# psc3 register map
Vendor: Infineon Technologies; Series: PSC3; File version: 1.0
CPU: CM33 r0p1, little endian, MPU, FPU, VTOR, 3 interrupt priority bits
Registers are 32-bit, read-write, reset 0x0 unless marked. A register's access mark holds for its fields unless they carry their own. Offsets are from the block's base; [hi:lo] are bit positions; lines under a group give offsets from that group; {n}, {i} and the like mark numbered series; 'fields as' and 'values as' point back to an identical list; <NAME> marks a mode.

## SRSS (part 2 of 3) — SRSS Core Registers
Base 0x42200000
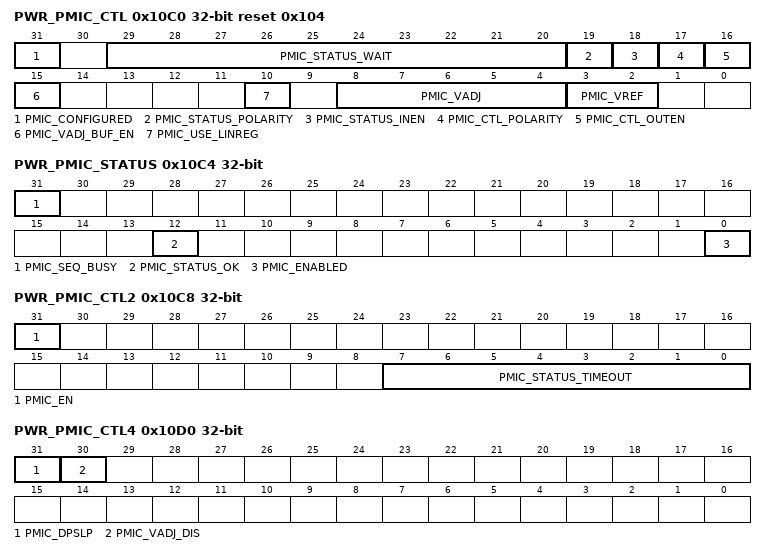
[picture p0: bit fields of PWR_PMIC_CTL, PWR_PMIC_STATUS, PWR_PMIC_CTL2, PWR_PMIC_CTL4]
0x10C0 PWR_PMIC_CTL reset 0x104 — PMIC Control Register
  [31] PMIC_CONFIGURED — Indicates the PMIC has been configured. This is used to know if PMIC should be enabled in response to a debug power up request. Do not change PMIC settings after this bit is set high.
  [29:20] PMIC_STATUS_WAIT — Wait count in 4us steps after PMIC status ok. This is used by the hardware sequencer to allow additional settling time before disabling the internal regulator. The LSB is 32 IMO periods which results in a nominal LSB step of 4us.
  [19] PMIC_STATUS_POLARITY — The polarity used to trigger a reset action based on the PMIC status input. The reset system triggers a reset when the unmasked PMIC status matches this value.
  [18] PMIC_STATUS_INEN — Input buffer enable for PMIC status input. Set this bit high to enable the input receiver.
  [17] PMIC_CTL_POLARITY — Polarity used to enable the PMIC. The sequencer uses PMIC_CTL_POLARITY to enable the PMIC, and it uses the complement to disable the PMIC.
  [16] PMIC_CTL_OUTEN — Output enable for PMIC enable pin. Set this bit high to enable the driver on this pin.
  [15] PMIC_VADJ_BUF_EN — Analog buffer enable on voltage adjust output. Write this bit depending on the type of PMIC connected: 0: Bypass buffer. This connects the resistor divider directly to the output pin. Use this setting for a PMIC with a high-impedance feedback input, such as those that support a resistor divider on the PCB. This setting can also be used with a low-impedance PMIC with PMIC_VREF=2'b11 (no scaling). 1: Use analog buffer. This enables an analog buffer between the resistor divider output and the pin. The buffer can drive a resistor divider on the PCB that feeds into the PMIC feedback input. This allows targeting a different PMIC reference voltage from PMIC_VREF choices, while still supporting voltage adjustment using the internal divider.
  [10] PMIC_USE_LINREG — Controls whether hardware sequencer keeps the internal Active Linear Regulator enabled to improve supply supervision of vccd. When using this feature, if the PMIC fails to keep vccd above the internal regulator target, then the internal regulator will attempt to recover vccd. If the regulator current is too high, the regulator triggers an over-current detector (OCD) reset. 0: Internal Active Linear Regulator disabled after PMIC enabled. OCD is disabled.; 1: Internal Active Linear Regulator kept enabled. See datasheet for minimum PMIC vccd input to prevent OCD.
  [8:4] PMIC_VADJ — Voltage adjustment output setting. The lookup table in this field requires the proper setting in PMIC_VREF for the chosen PMIC. This field has no effect when PMIC_VREF selects no scaling. The feedback tap point is at a vccd pad inside the chip, so the voltage may be a little higher at the PMIC output. 0x03: 1.040V, 0x04: 1.049V, 0x05: 1.057V, 0x06: 1.066V, 0x07: 1.074V, 0x08: 1.083V, 0x09: 1.091V, 0x0A: 1.099V, 0x0B: 1.108V, 0x0C: 1.116V, 0x0D: 1.125V, 0x0E: 1.133V, 0x0F: 1.142V, 0x10: 1.150V, 0x11: 1.158V, 0x12: 1.167V, 0x13: 1.175V, 0x14: 1.184V, 0x15: 1.192V, 0x16: 1.201V, 0x17: 1.209V, 0x18: 1.218V, 0x19: 1.226V, 0x1A: 1.234V, 0x1B: 1.243V, 0x1C: 1.251V, others: Illegal. Behavior is undefined.
  [3:2] PMIC_VREF — PMIC reference voltage setting. This selects the scaling factor used to generate the output voltage (vout) given the feedback voltage (vfb) for the chosen PMIC. For a PMIC that compares vfb to an internal reference voltage (vref) according to the formula vout=vref/vfb, select that vref below. For a PMIC that contains an internal resistor divider and expects an unscaled feedback voltage, use the 'No scaling' choice. 2'b00: Scale for vref=0.9V, use PMIC_VADJ to set the vccd target; 2'b01: Scale for vref=0.8V, use PMIC_VADJ to set the vccd target; 2'b10: Scale for vref=0.6V, use PMIC_VADJ to set the vccd target; 2'b11: No scaling, PMIC_VADJ has no effect
0x10C4 PWR_PMIC_STATUS ro — PMIC Status Register
  [31] PMIC_SEQ_BUSY — Indicates the PMIC enable/disable sequencer is busy transitioning to/from PMIC. 0: Sequencer is not busy; 1: Sequencer is busy either enabling or disabling PMIC.
  [12] PMIC_STATUS_OK — Indicates the PMIC status is ok. This includes polarity adjustment according to PMIC_STATUS_POLARITY. 0: PMIC status is not ok or PMIC input buffer is disabled (PMIC_STATUS_INEN==0); 1: PMIC status input buffer is enabled and indicates ok
  [0] PMIC_ENABLED — Indicates the state of the PMIC enable/disable sequencer. This bit is only valid when PMIC_SEQ_BUSY==0. 0: PMIC sequencer indicates PMIC is disabled. 1: PMIC sequencer indicates PMIC is enabled.
0x10C8 PWR_PMIC_CTL2 — PMIC Control Register 2
  [31] PMIC_EN — Enable PMIC. This bit will not set if PMIC_CONFIGURED==0. Use PWR_PMIC_STATUS.ENABLED to know the actual status of PMIC. It will differ from this bit in the following cases: A) Do not enter DEEPSLEEP while the sequencer is busy (see PWR_PMIC_STATUS.PMIC_SEQ_BUSY). The hardware sequencer disables PMIC during DEEPSLEEP entry and enables it upon wakeup. B) The debugger requests the chip remain powered up. Hardware prevents PMIC from disabling when this bit is cleared. Hardware does not automatically enable PMIC in response to debugger power up request. If this bit is low when the debugger deasserts the power up request, the hardware sequencer will disable PMIC.
  [7:0] PMIC_STATUS_TIMEOUT — Timeout while waiting for PMIC_STATUS_OK==1 when switching to PMIC. 0: disables timeout. Do not change this register after setting PWR_PMIC_CTL.PMIC_CONFIGURED. >0: enables timeout of PMIC_STATUS_TIMEOUT*128us (nominal, clocked by IMO). Timeout expiration triggers reset.
0x10D0 PWR_PMIC_CTL4 — PMIC Control Register 4
  [31] PMIC_DPSLP — Configures PMIC behavior during DEEPSLEEP. 0: Device operates from internal regulators during DEEPSLEEP. If PMIC is enabled at the beginning of the DEEPSLEEP transition, hardware changes to the internal regulators and disables the PMIC. 1: DEEPSLEEP transition does not change PMIC enable.
  [30] PMIC_VADJ_DIS — Disables the VADJ circuitry. This can be used to decrease current consumption if the entire feedback network is outside the device. 0: Device generates VADJ when PMIC is enabled. This allows the feedback loop to compensate for voltage drops in the PCB and package. 1: Device does not generate VADJ, and it must not be part of the PMIC feedback loop. This reduces current by turning off the internal resistor divider that generates VADJ.
{0x1200+4i} CLK_PATH_SELECT[{i}] (i=0..15) — Clock Path Select Register
  [2:0] PATH_MUX — Selects a source for clock PATH<i>. Note that not all products support all clock sources. Selecting a clock source that is not supported will result in undefined behavior. It takes four cycles of the originally selected clock to switch away from it. Do not disable the original clock during this time.
    0=IMO (IMO - Internal R/C Oscillator); 1=EXTCLK (EXTCLK - External Clock Pin); 2=ECO (ECO - External-Crystal Oscillator); 3=ALTHF (ALTHF - Alternate High-Frequency clock input (product-specific clock)); 4=DSI_MUX (DSI_MUX - Output of DSI mux for this path. Using a DSI source directly as root of HFCLK will result in undefined behavior.); 5=LPECO (LPECO - Low-Power External-Crystal Oscillator); 6=IHO (IHO - Internal High-speed Oscillator)
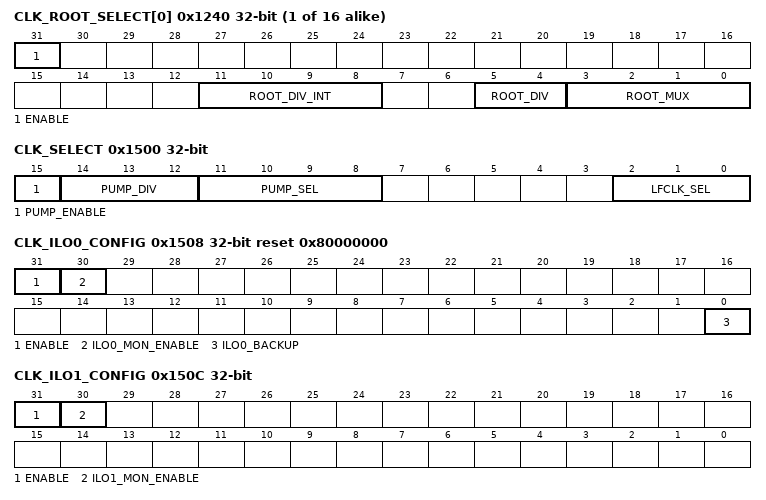
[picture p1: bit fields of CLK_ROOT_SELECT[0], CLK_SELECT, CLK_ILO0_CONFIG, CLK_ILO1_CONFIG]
{0x1240+4i} CLK_ROOT_SELECT[{i}] (i=0..15) — Clock Root Select Register
  [31] ENABLE — Enable for this clock root. All clock roots default to disabled (ENABLE==0) except HFCLK0, which cannot be disabled.
  [11:8] ROOT_DIV_INT — Selects predivider value for this clock root and DSI input. This divider is after DIRECT_MUX. For products with DSI, the output of this mux is routed to DSI for use as a signal. For products with clock supervision, the output of this mux is the monitored clock for CSV_HF<k>.
    0=NO_DIV (Transparent mode, feed through selected clock source w/o dividing.); {v}=DIV_BY_{v+1} (Divide selected clock source by {v+1}) (v=1..15)
  [5:4] ROOT_DIV — Obsolete. Do not use in new designs.
  [3:0] ROOT_MUX — Selects a clock path for HFCLK<k> and SRSS DSI input <k>. The output of this mux goes to the direct mux (see CLK_DIRECT_SELECT). Use CLK_SELECT_PATH[i] to configure the desired path. The number of clock paths is product-specific, and selecting an unimplemented path is not supported. Some paths may have FLL or PLL available (product-specific), and the control and bypass mux selections of these are in other registers. Configure the FLL using CLK_FLL_CONFIG register. Configure a PLL using the related CLK_PLL_CONFIG[k] register. Note that not all products support all clock sources. Selecting a clock source that is not supported will result in undefined behavior. It takes four cycles of the originally selected clock to switch away from it. Do not disable the original clock during this time.
    {v}=PATH{v} (Select PATH{v}) (v=0..15)
{0x1280+4i} CLK_DIRECT_SELECT[{i}] (i=0..15) — Clock Root Direct Select Register
  [8] DIRECT_MUX — Direct selection mux that allows IMO to bypass most of the clock mux structure. For products with multiple regulators, this mux can be used to reduce current without requiring significant reconfiguration of the clocking network. The default value of HFCLK<0>==ROOT_MUX, and the default value for other clock trees is product-specific.
    0=IMO (Select IMO); 1=ROOT_MUX (Select ROOT_MUX selection)
0x1400 CSV_HF group — Clock Supervisor (CSV) registers for Root clocks
  {0x0+0x10*j} CSV[{j}] (j=0..6) group — Active domain Clock Supervisor (CSV) registers
    0x00 REF_CTL — Clock Supervision Reference Control
      [31] CSV_EN — Enables clock supervision, both frequency and loss. CSV in Active domain: Clock supervision is reset during DeepSleep and Hibernate modes. When enabled it begins operating automatically after a DeepSleep wakeup, but it must be reconfigured after Hibernate wakeup. CSV in DeepSleep domain: Clock supervision is reset during Hibernate mode. It must be reconfigured after Hibernate wakeup. A CSV error detection is reported to the Fault structure, or instead it can generate a power reset.
      [30] CSV_ACTION — Specifies the action taken when an anomaly is detected on the monitored clock. CSV in DeepSleep domain always do a Fault report (which also wakes up the system).
        0=FAULT (Generate a fault); 1=RESET (Cause a power reset. This should only be used for clk_hf0.)
      [15:0] STARTUP — Startup delay time -1 (in reference clock cycles), after enable or DeepSleep wakeup, from reference clock start to monitored clock start. At a minimum (both clocks running): STARTUP >= (PERIOD +3) * FREQ_RATIO - UPPER, with FREQ_RATIO = (Reference frequency / Monitored frequency) On top of that the actual clock startup delay and the margin for accuracy of both clocks must be added.
    0x04 REF_LIMIT — Clock Supervision Reference Limits
      [31:16] UPPER — Cycle time upper limit. Set the upper limit -1, in reference clock cycles, before (or same time) the next monitored clock event must happen. If a monitored clock event does not happen before this limit is reached, or does not happen at all (clock loss), a CSV error is detected.
      [15:0] LOWER — Cycle time lower limit. Set the lower limit -1, in reference clock cycles, before the next monitored clock event is allowed to happen. If a monitored clock event happens before this limit is reached a CSV error is detected. LOWER must be at least 1 less than UPPER. In case the clocks are asynchronous LOWER must be at least 3 less than UPPER.
    0x08 MON_CTL — Clock Supervision Monitor Control
      [15:0] PERIOD — Period time. Set the Period -1, in monitored clock cycles, before the next monitored clock event happens. PERIOD <= (UPPER+1) / FREQ_RATIO -1, with FREQ_RATIO = (Reference frequency / Monitored frequency) In case the clocks are asynchronous: PERIOD <= UPPER / FREQ_RATIO -1 Additionally margin must be added for accuracy of both clocks.
0x1500 CLK_SELECT — Clock selection register
  [15] PUMP_ENABLE — Enable the pump clock. PUMP_ENABLE and the PUMP_SEL mux are not glitch-free to minimize side-effects, avoid changing the PUMP_SEL and PUMP_DIV while changing PUMP_ENABLE. To change the settings, do the following: 1) If the pump clock is enabled, write PUMP_ENABLE=0 without changing PUMP_SEL and PUMP_DIV. 2) Change PUMP_SEL and PUMP_DIV to desired settings with PUMP_ENABLE=0. 3) Write PUMP_ENABLE=1 without changing PUMP_SEL and PUMP_DIV.
  [14:12] PUMP_DIV — Division ratio for PUMPCLK. Uses selected PUMP_SEL clock as the source.
    0=NO_DIV (Transparent mode, feed through selected clock source w/o dividing.); 1=DIV_BY_2 (Divide selected clock source by 2); 2=DIV_BY_4 (Divide selected clock source by 4); 3=DIV_BY_8 (Divide selected clock source by 8); 4=DIV_BY_16 (Divide selected clock source by 16)
  [11:8] PUMP_SEL — Selects clock PATH<k>, where k=PUMP_SEL. The output of this mux goes to the PUMP_DIV to make PUMPCLK Each product has a specific number of available clock paths. Selecting a path that is not implemented on a product will result in undefined behavior. Note that this is not a glitch free mux.
  [2:0] LFCLK_SEL — Select source for LFCLK. Note that not all products support all clock sources. Selecting a clock source that is not supported will result in undefined behavior. Writes to this field are ignored unless the WDT is unlocked using WDT_LOCK register. It takes four cycles of the originally selected clock to switch away from it. Do not disable the original clock during this time.
    0=ILO (ILO - Internal Low-speed Oscillator); 1=WCO (WCO - Watch-Crystal Oscillator. Requires Backup domain to be present and properly configured (including external watch crystal, if used).); 2=ALTLF (ALTLF - Alternate Low-Frequency Clock. Capability is product-specific); 3=PILO (PILO - Precision ILO, if present.); 4=ILO1 (ILO1 - Internal Low-speed Oscillator #1, if present.); 5=ECO_PRESCALER (ECO_PRESCALER - External-Crystal Oscillator after prescaling, if present. Does not work in DEEPSLEEP or HIBERNATE modes. Intended for applications that operate in ACTIVE/SLEEP modes only. This option is only valid when ECO is present in the product. Not compatible with an clk_sys frequency <48MHz.); 6=LPECO_PRESCALER (LPECO_PRESCALER - Low-Power External-Crystal Oscillator after prescaling, if present. This choice works in ACTIVE/SLEEP/DEEPSLEEP modes. This option is only valid when LPECO is present in the product.)
0x1508 CLK_ILO0_CONFIG reset 0x80000000 — ILO0 Configuration
  [31] ENABLE — Master enable for ILO. Writes to this field are ignored unless the WDT is unlocked using WDT_LOCK register. HT-variant: This register will not clear unless PWR_CTL2.BGREF_LPMODE==0. After enabling, the first ILO0 cycle occurs within 12us and is +/-10 percent accuracy. Thereafter, ILO0 is +/-5 percent accurate.
  [30] ILO0_MON_ENABLE
  [0] ILO0_BACKUP — This register indicates that ILO0 should stay enabled during XRES and HIBERNATE modes. If backup voltage domain is implemented on the product, this bit also indicates if ILO0 should stay enabled through power-related resets on other supplies, e.g.. BOD on VDDD/VCCD. Writes to this field are ignored unless the WDT is unlocked. This register is reset when the backup logic resets. 0: ILO0 turns off during XRES, HIBERNATE, and power-related resets. ILO0 configuration and trims are reset by these events. 1: ILO0 stays enabled, as described above. ILO0 configuration and trims are not reset by these events.
0x150C CLK_ILO1_CONFIG — ILO1 Configuration
  [31] ENABLE — Master enable for ILO1. HT-variant: After enabling, the first ILO1 cycle occurs within 12us and is +/-10 percent accuracy. Thereafter, ILO1 is +/-5 percent accurate.
  [30] ILO1_MON_ENABLE
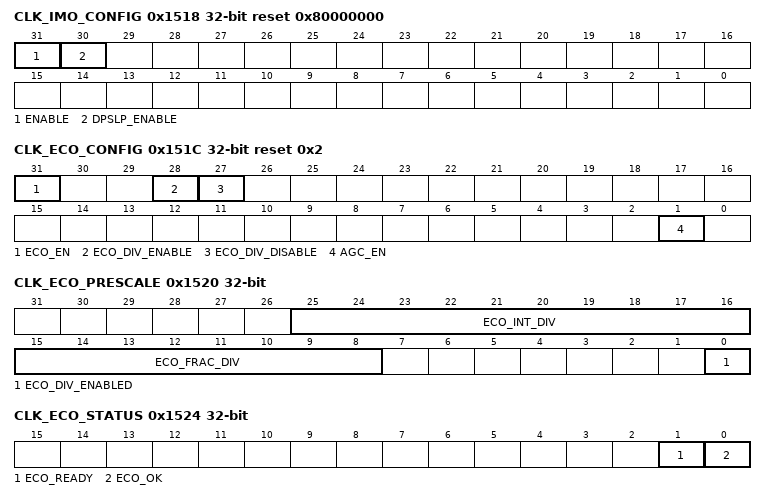
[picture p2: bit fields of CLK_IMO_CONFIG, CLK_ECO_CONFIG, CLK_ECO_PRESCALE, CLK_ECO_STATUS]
0x1518 CLK_IMO_CONFIG reset 0x80000000 — IMO Configuration
  [31] ENABLE — Master enable for IMO oscillator. This bit must be high at all times for all functions to work properly. Hardware will automatically disable the IMO during HIBERNATE and XRES. It will automatically disable during DEEPSLEEP if DPSLP_ENABLE==0.
  [30] DPSLP_ENABLE — Enable for IMO during DEEPSLEEP. This bit configures IMO behavior during DEEPSLEEP: 0: IMO is automatically disabled during DEEPSLEEP and enables upon wakeup; 1: IMO is kept enabled throughout DEEPSLEEP
0x151C CLK_ECO_CONFIG reset 0x2 — ECO Configuration Register
  [31] ECO_EN — Master enable for ECO oscillator. Configure the settings in CLK_ECO_CONFIG2 to work with the selected crystal, before enabling ECO.
  [28] ECO_DIV_ENABLE — ECO prescaler enable command (mutually exclusive with ECO_DIV_DISABLE). ECO Prescaler only works in ACTIVE and SLEEP modes. SW sets this field to '1' to enable the divider and HW sets this field to '0' to indicate that divider enabling has completed. When the divider is enabled, its integer and fractional counters are initialized to '0'. If a divider is to be re-enabled using different integer and fractional divider values, the SW should follow these steps: 0: Disable the divider using the ECO_DIV_DISABLE field. 1: Configure CLK_ECO_PRESCALE registers. 2: Enable the divider using the ECO_DIV_ENABLE field. HW sets the ECO_DIV_ENABLE field to '0' when the enabling is performed and HW set CLK_ECO_PRESCALER.ENABLED to '1' when the enabling is performed.
  [27] ECO_DIV_DISABLE — ECO prescaler disable command (mutually exclusive with ECO_DIV_ENABLE). SW sets this field to '1' and HW sets this field to '0'. HW sets ECO_DIV_DISABLE field to '0' immediately and HW sets CLK_ECO_PRESCALE.ECO_DIV_EN field to '0' immediately.
  [1] AGC_EN — Automatic Gain Control (AGC) enable. When set, the oscillation amplitude is controlled to the level selected by CLK_ECO_CONFIG2.ATRIM. When low, the amplitude is not explicitly controlled and can be as high as the vddd supply. WARNING: use care when disabling AGC because driving a crystal beyond its rated limit can permanently damage the crystal.
0x1520 CLK_ECO_PRESCALE — ECO Prescaler Configuration Register
  [25:16] ECO_INT_DIV — 10-bit integer value allows for ECO frequencies up to 33.55MHz. Subtract one from the desired divide value when writing this field. For example, to divide by 1, write ECO_INT_DIV=0. Do not change this setting when ECO Prescaler is enabled.
  [15:8] ECO_FRAC_DIV — 8-bit fractional value, sufficient to get prescaler output within the +/-65ppm calibration range. Do not change this setting when ECO Prescaler is enabled.
  [0] ECO_DIV_ENABLED ro — ECO prescaler enabled. HW sets this field to '1' as a result of an CLK_ECO_CONFIG.ECO_DIV_ENABLE command. HW sets this field to '0' as a result on a CLK_ECO_CONFIG.ECO_DIV_DISABLE command. ECO prescaler is incompatible with DEEPSLEEP modes, and firmware must disable it before entering DEEPSLEEP.
0x1524 CLK_ECO_STATUS ro — ECO Status Register
  [1] ECO_READY — Indicates the ECO internal oscillator circuit has had enough time to fully stabilize. This is the output of a counter since ECO was enabled, and it does not check the ECO output. It is recommended to also confirm ECO_OK==1.
  [0] ECO_OK — Indicates the ECO internal oscillator circuit has sufficient amplitude. It may not meet the PPM accuracy or duty cycle spec.
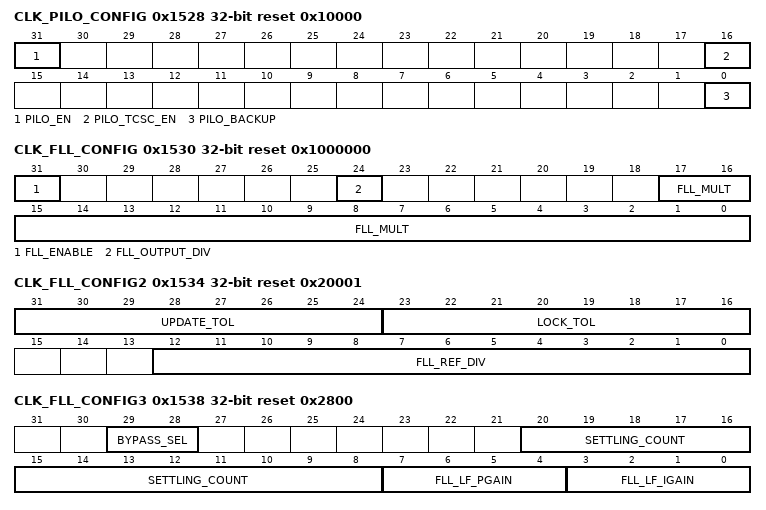
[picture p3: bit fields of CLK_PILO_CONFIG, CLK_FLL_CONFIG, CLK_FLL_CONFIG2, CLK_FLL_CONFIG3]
0x1528 CLK_PILO_CONFIG reset 0x10000 — Precision ILO Configuration Register
  [31] PILO_EN — Enable PILO. If the PILO is the selected source for WDT, writes to this field are ignored unless the WDT is unlocked using WDT_LOCK register.
  [16] PILO_TCSC_EN — PILO second order temperature curvature correction enable. If the PILO is the selected source for WDT, writes to this field are ignored unless the WDT is unlocked using WDT_LOCK register. 0: Disable second order temperature curvature correction. 1: Enable second order temperature curvature correction.
  [0] PILO_BACKUP — If backup domain is present on this product, this register indicates that PILO should stay enabled for use by backup domain during XRES, and HIBERNATE mode. If backup voltage domain is implemented on the product, PILO should stay enabled through power-related resets on other supplies, e.g.. BOD on VDDD/VCCD. If the PILO is the selected source for WDT, writes to this field are ignored unless the WDT is unlocked using WDT_LOCK register. 0: PILO turns off at XRES/BOD events. (unless backup voltage domain is implemented on the product) 1: PILO remains on if backup domain is present and powered even for XRES/BOD or HIBERNATE entry.
0x1530 CLK_FLL_CONFIG reset 0x1000000 — FLL Configuration Register
  [31] FLL_ENABLE — Master enable for FLL. The FLL requires firmware sequencing when enabling and disabling. Hardware handles sequencing automatically when entering/exiting DEEPSLEEP. To enable the FLL, use the following sequence: 1) Configure FLL and CCO settings. Do not modify CLK_FLL_CONFIG3.BYPASS_SEL (must be AUTO) or CLK_FLL_CONFIG.FLL_ENABLE (must be 0). 2) Enable the CCO by writing CLK_FLL_CONFIG4.CCO_ENABLE=1 3) Wait until CLK_FLL_STATUS.CCO_READY==1. 4) Ensure the reference clock has stabilized. 5) Write FLL_ENABLE=1. 6) Optionally wait until CLK_FLL_STATUS.LOCKED==1. The hardware automatically changes to the FLL output when LOCKED==1. To disable the FLL, use the following sequence: 1) Write CLK_FLL_CONFIG3.BYPASS_SEL=FLL_REF. 2) Read CLK_FLL_CONFIG3.BYPASS_SEL to ensure the write completes (read is not optional). 3) Wait at least ten cycles of either FLL reference clock or FLL output clock, whichever is slower. 4) Disable FLL with FLL_ENABLE=0. 5) Disable the CCO by writing CLK_FLL_CONFIG4.CCO_ENABLE=0. 6) Write CLK_FLL_CONFIG3.BYPASS_SEL=AUTO. 7) Read CLK_FLL_CONFIG3.BYPASS_SEL to ensure the write completes (read is not optional). 8) Wait three cycles of FLL reference clock. 0: Block is powered off 1: Block is powered on
  [24] FLL_OUTPUT_DIV — Control bits for Output divider. Set the divide value before enabling the FLL, and do not change it while FLL is enabled. 0: no division 1: divide by 2
  [17:0] FLL_MULT — Multiplier to determine CCO frequency in multiples of the frequency of the selected reference clock (Fref). Ffll = (FLL_MULT) * (Fref / REFERENCE_DIV) / (OUTPUT_DIV+1)
0x1534 CLK_FLL_CONFIG2 reset 0x20001 — FLL Configuration Register 2
  [31:24] UPDATE_TOL — Update tolerance sets the error threshold for when the FLL will update the CCO frequency settings. The update tolerance is the allowed difference between the count value for the ideal formula and the measured value. UPDATE_TOL should be less than LOCK_TOL.
  [23:16] LOCK_TOL — Lock tolerance sets the error threshold for when the FLL output is considered locked to the reference input. A high tolerance can be used to lock more quickly or allow less accuracy. The tolerance is the allowed difference between the count value for the ideal formula and the measured value. 0: tolerate error of 1 count value 1: tolerate error of 2 count values ... 255: tolerate error of 256 count values
  [12:0] FLL_REF_DIV — Control bits for reference divider. Set the divide value before enabling the FLL, and do not change it while FLL is enabled. 0: illegal (undefined behavior) 1: divide by 1 ... 8191: divide by 8191
0x1538 CLK_FLL_CONFIG3 reset 0x2800 — FLL Configuration Register 3
  [29:28] BYPASS_SEL — Bypass mux located just after FLL output. This register can be written while the FLL is enabled. When changing BYPASS_SEL, do not turn off the reference clock or CCO clock for five cycles (whichever is slower). Whenever BYPASS_SEL is changed, it is required to read CLK_FLL_CONFIG3 to ensure the change takes effect.
    0=AUTO (Automatic using lock indicator. When unlocked, automatically selects FLL reference input (bypass mode). When locked, automatically selects FLL output. This can allow some processing to occur while the FLL is locking, such as after DEEPSLEEP wakeup. It is incompatible with clock supervision, because the frequency changes based on the lock signal.); 1=LOCKED_OR_NOTHING (Similar to AUTO, except the clock is gated off when unlocked. This is compatible with clock supervision, because the supervisors allow no clock during startup (until a timeout occurs), and the clock targets the proper frequency whenever it is running.); 2=FLL_REF (Select FLL reference input (bypass mode). Ignores lock indicator); 3=FLL_OUT (Select FLL output. Ignores lock indicator.)
  [20:8] SETTLING_COUNT — Number of undivided reference clock cycles to wait after changing the CCO trim until the loop measurement restarts. A delay allows the CCO output to settle and gives a more accurate measurement. The default is tuned to an 8MHz reference clock since the IMO is expected to be the most common use case. 0: no settling time 1: wait one reference clock cycle ... 8191: wait 8191 reference clock cycles
  [7:4] FLL_LF_PGAIN — FLL Loop Filter Gain Setting #2. The proportional gain is the sum of FLL_LF_IGAIN and FLL_LF_PGAIN. 0: 1/256 1: 1/128 2: 1/64 3: 1/32 4: 1/16 5: 1/8 6: 1/4 7: 1/2 8: 1.0 9: 2.0 10: 4.0 11: 8.0 >=12: illegal
  [3:0] FLL_LF_IGAIN — FLL Loop Filter Gain Setting #1. The proportional gain is the sum of FLL_LF_IGAIN and FLL_LF_PGAIN. 0: 1/256 1: 1/128 2: 1/64 3: 1/32 4: 1/16 5: 1/8 6: 1/4 7: 1/2 8: 1.0 9: 2.0 10: 4.0 11: 8.0 >=12: illegal
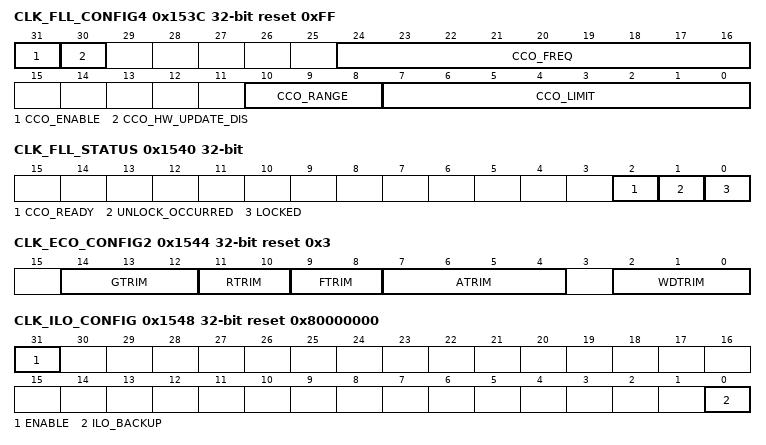
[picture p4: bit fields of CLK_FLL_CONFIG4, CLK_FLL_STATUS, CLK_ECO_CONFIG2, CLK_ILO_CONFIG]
0x153C CLK_FLL_CONFIG4 reset 0xFF — FLL Configuration Register 4
  [31] CCO_ENABLE — Enable the CCO. It is required to enable the CCO before using the FLL. 0: Block is powered off 1: Block is powered on
  [30] CCO_HW_UPDATE_DIS — Disable CCO frequency update by FLL hardware 0: Hardware update of CCO settings is allowed. Use this setting for normal FLL operation. 1: Hardware update of CCO settings is disabled. Use this setting for open-loop FLL operation.
  [24:16] CCO_FREQ — CCO frequency code. This is updated by HW when the FLL is enabled. It can be manually updated to use the CCO in an open loop configuration. The meaning of each frequency code depends on the range.
  [10:8] CCO_RANGE — Frequency range of CCO
    0=RANGE0 (Target frequency is in range [48, 64) MHz); 1=RANGE1 (Target frequency is in range [64, 85) MHz); 2=RANGE2 (Target frequency is in range [85, 113) MHz); 3=RANGE3 (Target frequency is in range [113, 150) MHz); 4=RANGE4 (Target frequency is in range [150, 200] MHz)
  [7:0] CCO_LIMIT — Maximum CCO offset allowed (used to prevent FLL dynamics from selecting an CCO frequency that the logic cannot support)
0x1540 CLK_FLL_STATUS — FLL Status Register
  [2] CCO_READY ro — This indicates that the CCO is internally settled and ready to use.
  [1] UNLOCK_OCCURRED — This bit sets whenever the FLL is enabled and goes out of lock. This bit stays set until cleared by firmware. Note: When exiting Deep Sleep with FLL enabled, UNLOCK_OCCURRED will set. Therefore, after FLL successfully locks, FW should clear UNLOCK_OCCURRED flag to prevent a false positive that would indicate that FLL erroneously unlocked.
  [0] LOCKED ro — FLL Lock Indicator
0x1544 CLK_ECO_CONFIG2 reset 0x3 — ECO Configuration Register 2
  [14:12] GTRIM — Gain Trim - Startup time.
  [11:10] RTRIM — Feedback resistor Trim
  [9:8] FTRIM — Filter Trim - 3rd harmonic oscillation
  [7:4] ATRIM — Amplitude trim to set the crystal drive level when ECO_CONFIG.AGC_EN=1. WARNING: use care when setting this field because driving a crystal beyond its rated limit can permanently damage the crystal. 0x0 - 150mV 0x1 - 175mV 0x2 - 200mV 0x3 - 225mV 0x4 - 250mV 0x5 - 275mV 0x6 - 300mV 0x7 - 325mV 0x8 - 350mV 0x9 - 375mV 0xA - 400mV 0xB - 425mV 0xC - 450mV 0xD - 475mV 0xE - 500mV 0xF - 525mV
  [2:0] WDTRIM — Watch Dog Trim - Delta voltage below steady state level 0x0 - 50mV 0x1 - 75mV 0x2 - 100mV 0x3 - 125mV 0x4 - 150mV 0x5 - 175mV 0x6 - 200mV 0x7 - 225mV
0x1548 CLK_ILO_CONFIG reset 0x80000000 — ILO Configuration
  [31] ENABLE — Master enable for ILO. Writes to this field are ignored unless the WDT is unlocked using WDT_LOCK register. After enabling, it takes at most two cycles to reach the accuracy spec.
  [0] ILO_BACKUP — If backup domain is present on this product, this register indicates that ILO should stay enabled for use by backup domain during XRES, HIBERNATE mode, and through power-related resets like BOD on VDDD/VCCD. Writes to this field are ignored unless the WDT is unlocked using WDT_LOCK register. 0: ILO turns off at XRES/BOD event or HIBERNATE entry. 1: ILO remains on if backup domain is present and powered even for XRES/BOD or HIBERNATE entry.
0x154C CLK_TRIM_ILO_CTL reset 0x2C — ILO Trim Register
  [5:0] ILO_FTRIM — IL0 frequency trims. LSB step size is 1.5 percent (typical) of the frequency.
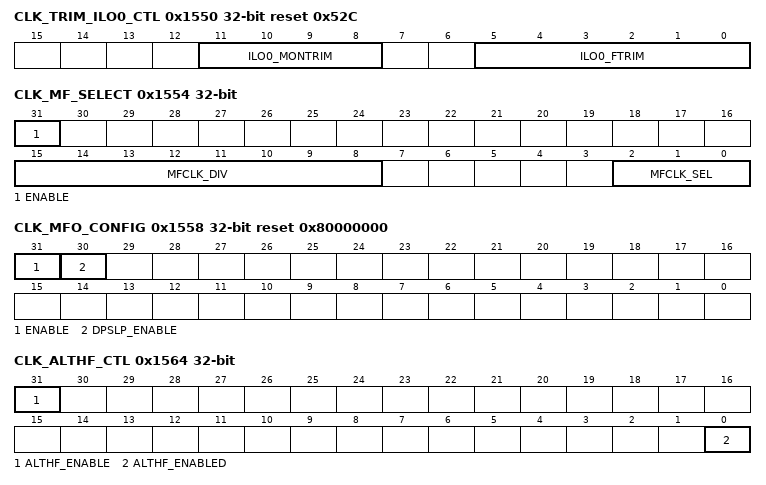
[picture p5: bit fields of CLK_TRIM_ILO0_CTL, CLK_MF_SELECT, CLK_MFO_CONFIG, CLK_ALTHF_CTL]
0x1550 CLK_TRIM_ILO0_CTL reset 0x52C — ILO0 Trim Register
  [11:8] ILO0_MONTRIM — ILO0 internal monitor trim.
  [5:0] ILO0_FTRIM — ILO0 frequency trims. LSB step size is 1.5 percent (typical) of the frequency.
0x1554 CLK_MF_SELECT — Medium Frequency Clock Select Register
  [31] ENABLE — Enable for MFCLK (clk_mf). When disabling clk_mf, do not disable the source until after 5 clk_mf periods. clk_mf continues to operate in DEEPSLEEP for compatible sources. Firmware must disable clk_mf before entering DEEPSLEEP if the source is not compatible with DEEPSLEEP mode.
  [15:8] MFCLK_DIV — Divide selected clock source by (1+MFCLK_DIV). The output of this divider is MFCLK (clk_mf). Allows for integer divisions in the range [1, 256]. Do not change this setting while ENABLE==1.
  [2:0] MFCLK_SEL — Select source for MFCLK (clk_mf). Note that not all products support all clock sources. Selecting a clock source that is not supported results in undefined behavior.
    0=MFO (MFO - Medium Frequency Oscillator. DEEPSLEEP compatibility is product-specific. See CLK_MFO_CONFIG for capability of this product.); 1=ILO (ILO - Internal Low-speed Oscillator.); 2=WCO (WCO - Watch-Crystal Oscillator, if present.); 3=ALTLF (ALTLF - Alternate Low-Frequency Clock. Capability is product-specific); 4=PILO (PILO - Precision ILO, if present.); 5=ILO1 (ILO1 - Internal Low-speed Oscillator #1, if present.); 6=ECO_PRESCALER (ECO_PRESCALER - External-Crystal Oscillator, if present, after prescaling in CLK_ECO_PRESCALE. Intended for applications that operate in ACTIVE/SLEEP modes only. Does not work in DEEPSLEEP mode.); 7=LPECO (LPECO - Low Power External Crystal Oscillator, if present.)
0x1558 CLK_MFO_CONFIG reset 0x80000000 — MFO Configuration Register
  [31] ENABLE — Enable for Medium Frequency Oscillator (MFO) to generate clk_mf. It is product-specific whether this is a separate component or implemented as a divided version of another clock (eg. IMO).
  [30] DPSLP_ENABLE — Enable for MFO during DEEPSLEEP. This bit is ignored when ENABLE==0. When ENABLE==1: 0: MFO is automatically disabled during DEEPSLEEP and enables upon wakeup; 1: MFO is kept enabled throughout DEEPSLEEP
0x1560 CLK_IHO_CONFIG reset 0x80000000 — IHO Configuration Register
  [31] ENABLE — Enable for Internal High-speed Oscillator (IHO) to generate clk_iho.
0x1564 CLK_ALTHF_CTL — Alternate High Frequency Clock Control Register
  [31] ALTHF_ENABLE — Enable for ALTHF clock when used by SRSS. There may be independent control of ALTHF by another subsystem, and this bit prevents ALTHF from being disabled when SRSS needs it. SRSS automatically removes its enable request during DEEPSLEEP and lower modes.
  [0] ALTHF_ENABLED ro — Indicates that ALTHF is actually enabled. The delay between a transition on ALTHF_ENABLE and ALTHF_ENABLED is product specific.
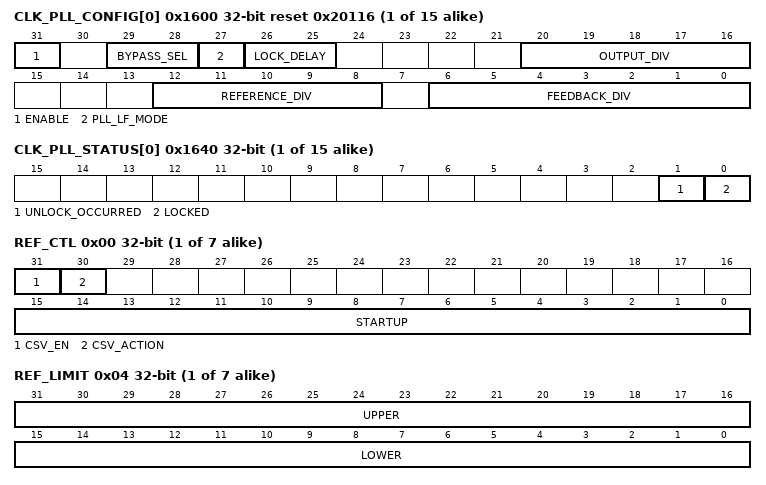
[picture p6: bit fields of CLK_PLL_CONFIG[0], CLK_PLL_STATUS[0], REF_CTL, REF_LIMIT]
{0x1600+4i} CLK_PLL_CONFIG[{i}] (i=0..14) reset 0x20116 — PLL Configuration Register
  [31] ENABLE — Master enable for PLL. Setup FEEDBACK_DIV, REFERENCE_DIV, and OUTPUT_DIV at least one cycle before setting ENABLE=1. Fpll = (FEEDBACK_DIV) * (Fref / REFERENCE_DIV) / (OUTPUT_DIV) 0: Block is disabled. When the PLL disables, hardware controls the bypass mux as described in BYPASS_SEL, before disabling the PLL circuit. 1: Block is enabled
  [29:28] BYPASS_SEL — Bypass mux located just after PLL output. This selection is glitch-free and can be changed while the PLL is running. When changing BYPASS_SEL, do not turn off the reference clock or PLL clock for five cycles (whichever is slower).
    0=AUTO (Automatic using lock indicator. When unlocked, automatically selects PLL reference input (bypass mode). When locked, automatically selects PLL output. If ENABLE=0, automatically selects PLL reference input.); 1=LOCKED_OR_NOTHING (Similar to AUTO, except the clock is gated off when unlocked. This is compatible with clock supervision, because the supervisors allow no clock during startup (until a timeout occurs), and the clock targets the proper frequency whenever it is running. If ENABLE=0, no clock is output.); 2=PLL_REF (Select PLL reference input (bypass mode). Ignores lock indicator); 3=PLL_OUT (Select PLL output. Ignores lock indicator. If ENABLE=0, no clock is output.)
  [27] PLL_LF_MODE — VCO frequency range selection. Configure this bit according to the targeted VCO frequency. Do not change this setting while the PLL is enabled. 0: VCO frequency is [200MHz, 400MHz] 1: VCO frequency is [170MHz, 200MHz)
  [26:25] LOCK_DELAY
  [20:16] OUTPUT_DIV — Control bits for Output divider. Set the divide value before enabling the PLL, and do not change it while PLL is enabled. 0: illegal (undefined behavior) 1: illegal (undefined behavior) 2: divide by 2. Suitable for direct usage as HFCLK source. ... 16: divide by 16. Suitable for direct usage as HFCLK source. >16: illegal (undefined behavior)
  [12:8] REFERENCE_DIV — Control bits for reference divider. Set the divide value before enabling the PLL, and do not change it while PLL is enabled. 0: illegal (undefined behavior) 1: divide by 1 ... 20: divide by 20 others: illegal (undefined behavior)
  [6:0] FEEDBACK_DIV — Control bits for feedback divider. Set the divide value before enabling the PLL, and do not change it while PLL is enabled. 0-21: illegal (undefined behavior) 22: divide by 22 ... 112: divide by 112 >112: illegal (undefined behavior)
{0x1640+4i} CLK_PLL_STATUS[{i}] (i=0..14) — PLL Status Register
  [1] UNLOCK_OCCURRED — This bit sets whenever the PLL Lock bit goes low, and stays set until cleared by firmware.
  [0] LOCKED ro — PLL Lock Indicator
0x1700 CSV_REF_SEL — Select CSV Reference clock for Active domain
  [2:0] REF_MUX — Selects a source for clock clk_ref_hf. Note that not all products support all clock sources. Selecting a clock source that is not supported will result in undefined behavior. It takes four cycles of the originally selected clock to switch away from it. Do not disable the original clock during this time.
    0=IMO (IMO - Internal R/C Oscillator); 1=EXTCLK (EXTCLK - External Clock Pin); 2=ECO (ECO - External-Crystal Oscillator); 3=ALTHF (ALTHF - Alternate High-Frequency clock input (product-specific clock)); 4=IHO (IHO - Internal High-speed Oscillator)
0x1710 CSV_REF group — CSV registers for the CSV Reference clock
  0x00 CSV group — Active domain Clock Supervisor (CSV) registers for CSV Reference clock
    0x00 REF_CTL — Clock Supervision Reference Control
      fields as CSV_HF.CSV[0].REF_CTL
    0x04 REF_LIMIT — Clock Supervision Reference Limits
      fields as CSV_HF.CSV[0].REF_LIMIT
    0x08 MON_CTL — Clock Supervision Monitor Control
      fields as CSV_HF.CSV[0].MON_CTL
0x1720 CSV_LF group — CSV registers for LF clock
  0x00 CSV group — LF clock Clock Supervisor registers
    0x00 REF_CTL — Clock Supervision Reference Control
      [31] CSV_EN — Enables clock supervision, both frequency and loss. CSV in Active domain: Clock supervision is reset during DeepSleep and Hibernate modes. When enabled it begins operating automatically after a DeepSleep wakeup, but it must be reconfigured after Hibernate wakeup. CSV in DeepSleep domain: Clock supervision is reset during Hibernate mode. It must be reconfigured after Hibernate wakeup. CSV in Backup domain: Clock supervision operates during Hibernate mode, can be configured to wake from Hibernate, and continues operating during reboot. A CSV error detection is reported to the Fault structure.
      [7:0] STARTUP — Startup delay time -1 (in reference clock cycles), after enable, from reference clock start to monitored clock start. At a minimum (both clocks running): STARTUP >= (PERIOD +3) * FREQ_RATIO - UPPER, with FREQ_RATIO = (Reference frequency / Monitored frequency) On top of that the actual clock startup delay and the margin for accuracy of both clocks must be added.
    0x04 REF_LIMIT — Clock Supervision Reference Limits
      [23:16] UPPER — Cycle time upper limit. Set the upper limit -1, in reference clock cycles, before (or same time) the next monitored clock event must happen. If a monitored clock event does not happen before this limit is reached, or does not happen at all (clock loss), a CSV error is detected.
      [7:0] LOWER — Cycle time lower limit. Set the lower limit -1, in reference clock cycles, before the next monitored clock event is allowed to happen. If a monitored clock event happens before this limit is reached a CSV error is detected. LOWER must be at least 1 less than UPPER. In case the clocks are asynchronous LOWER must be at least 3 less than UPPER.
    0x08 MON_CTL — Clock Supervision Monitor Control
      [7:0] PERIOD — Period time. Set the Period -1, in monitored clock cycles, before the next monitored clock event happens. PERIOD <= (UPPER+1) / FREQ_RATIO -1, with FREQ_RATIO = (Reference frequency / Monitored frequency) In case the clocks are asynchronous: PERIOD <= UPPER / FREQ_RATIO -1 Additionally margin must be added for accuracy of both clocks.
0x1730 CSV_ILO group — CSV registers for ILO clock
  0x00 CSV group — HVILO clock DeepSleep domain Clock Supervisor registers
    0x00 REF_CTL — Clock Supervision Reference Control
      fields as CSV_LF.CSV.REF_CTL
    0x04 REF_LIMIT — Clock Supervision Reference Limits
      fields as CSV_LF.CSV.REF_LIMIT
    0x08 MON_CTL — Clock Supervision Monitor Control
      fields as CSV_LF.CSV.MON_CTL
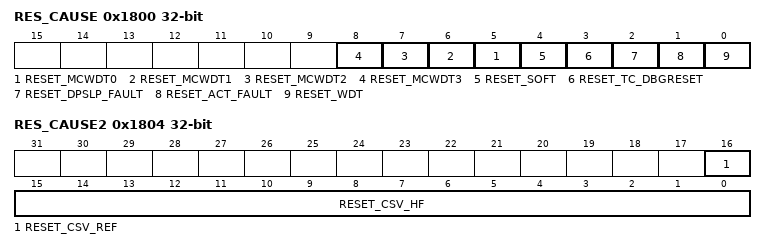
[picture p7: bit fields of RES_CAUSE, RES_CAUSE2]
0x1800 RES_CAUSE — Reset Cause Observation Register
  [n+5] RESET_MCWDT{n} (n=0..3) — Multi-Counter Watchdog timer reset #{n}. This is a low-voltage cause bit that hardware clears when the low-voltage supply is initialized (see comments above). This bit is only valid when parameter NUM_MCWDT>{n}
  [4] RESET_SOFT — A CPU requested a system reset through it's SYSRESETREQ. This can be done via a debugger probe or in firmware. This is a low-voltage cause bit that hardware clears when the low-voltage supply is initialized (see comments above).
  [3] RESET_TC_DBGRESET — Test controller or debugger asserted reset. Only resets debug domain. This is a low-voltage cause bit that hardware clears when the low-voltage supply is initialized (see comments above).
  [2] RESET_DPSLP_FAULT
  [1] RESET_ACT_FAULT
  [0] RESET_WDT — A basic WatchDog Timer (WDT) reset has occurred since last power cycle. ULP products: This is a low-voltage cause bit that hardware clears when the low-voltage supply is initialized (see comments above). For products that support high-voltage cause detection, this bit blocks recording of other high-voltage cause bits, except RESET_PORVDDD. Hardware clears this bit during POR. This bit is not blocked by other HV cause bits.
0x1804 RES_CAUSE2 — Reset Cause Observation Register 2
  [16] RESET_CSV_REF — Clock supervision logic requested a reset due to loss or frequency violation of the reference clock source that is used to monitor the other HF clock sources. This bit is only valid when parameter CSV_PRESENT is set.
  [15:0] RESET_CSV_HF — Clock supervision logic requested a reset due to loss or frequency violation of a high-frequency clock. Each bit index K corresponds to a HFCLK<K>. Unimplemented clock bits return zero. Each bit is only valid when the corresponding bit in parameter MASK_HFCSV is 1 and CSV_PRESENT is set.
